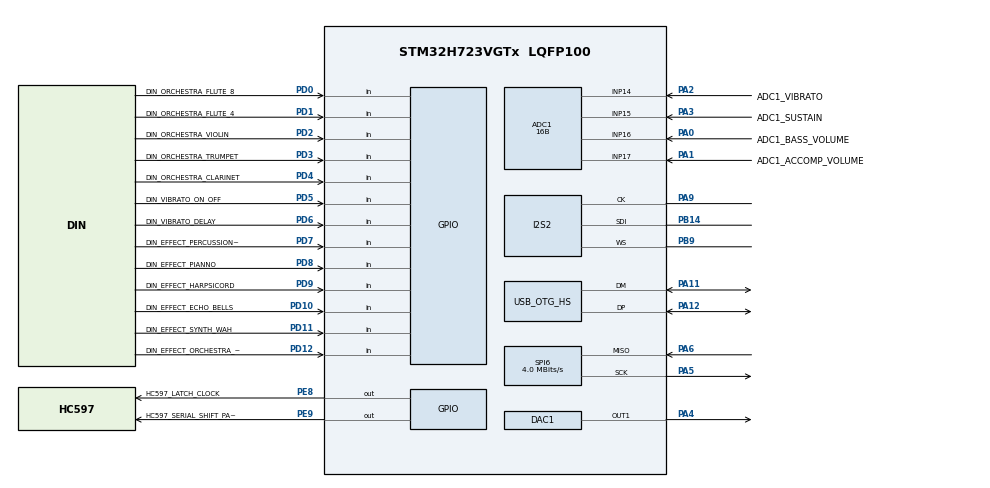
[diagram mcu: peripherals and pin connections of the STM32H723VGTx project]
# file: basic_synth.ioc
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ADC1.Channel-0\#ChannelRegularConversion=ADC_CHANNEL_14
ADC1.Channel-5\#ChannelRegularConversion=ADC_CHANNEL_15
ADC1.Channel-6\#ChannelRegularConversion=ADC_CHANNEL_16
ADC1.Channel-7\#ChannelRegularConversion=ADC_CHANNEL_17
ADC1.ClockPrescaler=ADC_CLOCK_SYNC_PCLK_DIV4
ADC1.ContinuousConvMode=ENABLE
ADC1.ConversionDataManagement=ADC_CONVERSIONDATA_DMA_CIRCULAR
ADC1.EOCSelection=ADC_EOC_SINGLE_CONV
ADC1.ExternalTrigConv=ADC_EXTERNALTRIG_T6_TRGO
ADC1.NbrOfConversion=4
ADC1.NbrOfConversionFlag=1
ADC1.OffsetNumber-0\#ChannelRegularConversion=ADC_OFFSET_NONE
ADC1.OffsetNumber-5\#ChannelRegularConversion=ADC_OFFSET_NONE
ADC1.OffsetNumber-6\#ChannelRegularConversion=ADC_OFFSET_NONE
ADC1.OffsetNumber-7\#ChannelRegularConversion=ADC_OFFSET_NONE
ADC1.OffsetSignedSaturation-0\#ChannelRegularConversion=DISABLE
ADC1.OffsetSignedSaturation-5\#ChannelRegularConversion=DISABLE
ADC1.OffsetSignedSaturation-6\#ChannelRegularConversion=DISABLE
ADC1.OffsetSignedSaturation-7\#ChannelRegularConversion=DISABLE
ADC1.Rank-0\#ChannelRegularConversion=1
ADC1.Rank-5\#ChannelRegularConversion=2
ADC1.Rank-6\#ChannelRegularConversion=3
ADC1.Rank-7\#ChannelRegularConversion=4
ADC1.Resolution=ADC_RESOLUTION_16B
ADC1.SamplingTime-0\#ChannelRegularConversion=ADC_SAMPLETIME_1CYCLE_5
ADC1.SamplingTime-5\#ChannelRegularConversion=ADC_SAMPLETIME_1CYCLE_5
ADC1.SamplingTime-6\#ChannelRegularConversion=ADC_SAMPLETIME_1CYCLE_5
ADC1.SamplingTime-7\#ChannelRegularConversion=ADC_SAMPLETIME_1CYCLE_5
ADC1.master=1
CORTEX_M7.default_mode_Activation=1
DAC1.DAC1_OutputBuffer-DAC_OUT1=DAC_OUTPUTBUFFER_ENABLE
DAC1.DAC_Channel-DAC_OUT1=DAC_CHANNEL_1
DAC1.DAC_Trigger-DAC_OUT1=DAC_TRIGGER_T7_TRGO
Dma.ADC1.0.Direction=DMA_PERIPH_TO_MEMORY
Dma.ADC1.0.EventEnable=DISABLE
Dma.ADC1.0.FIFOMode=DMA_FIFOMODE_DISABLE
Dma.ADC1.0.Instance=DMA2_Stream0
Dma.ADC1.0.MemDataAlignment=DMA_MDATAALIGN_WORD
Dma.ADC1.0.MemInc=DMA_MINC_ENABLE
Dma.ADC1.0.Mode=DMA_CIRCULAR
Dma.ADC1.0.PeriphDataAlignment=DMA_PDATAALIGN_WORD
Dma.ADC1.0.PeriphInc=DMA_PINC_DISABLE
Dma.ADC1.0.Polarity=HAL_DMAMUX_REQ_GEN_RISING
Dma.ADC1.0.Priority=DMA_PRIORITY_LOW
Dma.ADC1.0.RequestNumber=1
Dma.ADC1.0.SignalID=NONE
Dma.ADC1.0.SyncEnable=DISABLE
Dma.ADC1.0.SyncPolarity=HAL_DMAMUX_SYNC_NO_EVENT
Dma.ADC1.0.SyncRequestNumber=1
Dma.ADC1.0.SyncSignalID=NONE
Dma.DAC1_CH1.1.Direction=DMA_MEMORY_TO_PERIPH
Dma.DAC1_CH1.1.EventEnable=DISABLE
Dma.DAC1_CH1.1.FIFOMode=DMA_FIFOMODE_DISABLE
Dma.DAC1_CH1.1.Instance=DMA1_Stream0
Dma.DAC1_CH1.1.MemDataAlignment=DMA_MDATAALIGN_WORD
Dma.DAC1_CH1.1.MemInc=DMA_MINC_ENABLE
Dma.DAC1_CH1.1.Mode=DMA_CIRCULAR
Dma.DAC1_CH1.1.PeriphDataAlignment=DMA_PDATAALIGN_WORD
Dma.DAC1_CH1.1.PeriphInc=DMA_PINC_DISABLE
Dma.DAC1_CH1.1.Polarity=HAL_DMAMUX_REQ_GEN_RISING
Dma.DAC1_CH1.1.Priority=DMA_PRIORITY_LOW
Dma.DAC1_CH1.1.RequestNumber=1
Dma.DAC1_CH1.1.SignalID=NONE
Dma.DAC1_CH1.1.SyncEnable=DISABLE
Dma.DAC1_CH1.1.SyncPolarity=HAL_DMAMUX_SYNC_NO_EVENT
Dma.DAC1_CH1.1.SyncRequestNumber=1
Dma.DAC1_CH1.1.SyncSignalID=NONE
Dma.Request0=ADC1
Dma.Request1=DAC1_CH1
Dma.Request2=SPI2_RX
Dma.SPI2_RX.2.Direction=DMA_PERIPH_TO_MEMORY
Dma.SPI2_RX.2.EventEnable=DISABLE
Dma.SPI2_RX.2.FIFOMode=DMA_FIFOMODE_DISABLE
Dma.SPI2_RX.2.Instance=DMA1_Stream1
Dma.SPI2_RX.2.MemDataAlignment=DMA_MDATAALIGN_HALFWORD
Dma.SPI2_RX.2.MemInc=DMA_MINC_ENABLE
Dma.SPI2_RX.2.Mode=DMA_CIRCULAR
Dma.SPI2_RX.2.PeriphDataAlignment=DMA_PDATAALIGN_HALFWORD
Dma.SPI2_RX.2.PeriphInc=DMA_PINC_DISABLE
Dma.SPI2_RX.2.Polarity=HAL_DMAMUX_REQ_GEN_RISING
Dma.SPI2_RX.2.Priority=DMA_PRIORITY_HIGH
Dma.SPI2_RX.2.RequestNumber=1
Dma.SPI2_RX.2.SignalID=NONE
Dma.SPI2_RX.2.SyncEnable=DISABLE
Dma.SPI2_RX.2.SyncPolarity=HAL_DMAMUX_SYNC_NO_EVENT
Dma.SPI2_RX.2.SyncRequestNumber=1
Dma.SPI2_RX.2.SyncSignalID=NONE
I2S2.AudioFreq=AudioFreqCustomValue
I2S2.AudioFreqCustom=44100
I2S2.ErrorAudioFreq=0.15 %
I2S2.Instance=SPI$Index
I2S2.RealAudioFreq=44.07 KHz
Mcu.Family=STM32H7
Mcu.Name=STM32H723VGTx
Mcu.Package=LQFP100
NVIC.DMA1_Stream0_IRQn=true\:0\:0\:false\:false\:true\:false\:true\:true
NVIC.DMA1_Stream1_IRQn=true\:0\:0\:false\:false\:true\:false\:true\:true
NVIC.DMA2_Stream0_IRQn=true\:0\:0\:false\:false\:true\:false\:true\:true
NVIC.OTG_HS_IRQn=true\:0\:0\:false\:false\:true\:false\:true\:true
NVIC.PriorityGroup=NVIC_PRIORITYGROUP_4
PA0.GPIO_Label=ADC1_BASS_VOLUME
PA0.Mode=IN16-Single-Ended
PA0.Signal=ADC1_INP16
PA1.GPIO_Label=ADC1_ACCOMP_VOLUME
PA1.Mode=IN17-Single-Ended
PA1.Signal=ADC1_INP17
PA11.Mode=Device_Only_FS
PA11.Signal=USB_OTG_HS_DM
PA12.Mode=Device_Only_FS
PA12.Signal=USB_OTG_HS_DP
PA2.GPIO_Label=ADC1_VIBRATO
PA2.Signal=ADCx_INP14
PA3.GPIO_Label=ADC1_SUSTAIN
PA3.Signal=ADCx_INP15
PA4.Signal=COMP_DAC11_group
PA5.Mode=RX_Only_Simplex_Unidirect_Master
PA5.Signal=SPI6_SCK
PA6.Mode=RX_Only_Simplex_Unidirect_Master
PA6.Signal=SPI6_MISO
PA9.Mode=Half_Duplex_Master_Rx
PA9.Signal=I2S2_CK
PB14.Mode=Half_Duplex_Master_Rx
PB14.Signal=I2S2_SDI
PB9.Mode=Half_Duplex_Master_Rx
PB9.Signal=I2S2_WS
PD0.GPIO_Label=DIN_ORCHESTRA_FLUTE_8
PD0.GPIO_PuPd=GPIO_PULLUP
PD0.Signal=GPIO_Input
PD1.GPIO_Label=DIN_ORCHESTRA_FLUTE_4
PD1.GPIO_PuPd=GPIO_PULLUP
PD1.Signal=GPIO_Input
PD10.GPIO_Label=DIN_EFFECT_ECHO_BELLS
PD10.GPIO_PuPd=GPIO_PULLUP
PD10.Signal=GPIO_Input
PD11.GPIO_Label=DIN_EFFECT_SYNTH_WAH
PD11.GPIO_PuPd=GPIO_PULLUP
PD11.Signal=GPIO_Input
PD12.GPIO_Label=DIN_EFFECT_ORCHESTRA_CANCEL
PD12.GPIO_PuPd=GPIO_PULLUP
PD12.Signal=GPIO_Input
PD2.GPIO_Label=DIN_ORCHESTRA_VIOLIN
PD2.GPIO_PuPd=GPIO_PULLUP
PD2.Signal=GPIO_Input
PD3.GPIO_Label=DIN_ORCHESTRA_TRUMPET
PD3.GPIO_PuPd=GPIO_PULLUP
PD3.Signal=GPIO_Input
PD4.GPIO_Label=DIN_ORCHESTRA_CLARINET
PD4.GPIO_PuPd=GPIO_PULLUP
PD4.Signal=GPIO_Input
PD5.GPIO_Label=DIN_VIBRATO_ON_OFF
PD5.GPIO_PuPd=GPIO_PULLUP
PD5.Signal=GPIO_Input
PD6.GPIO_Label=DIN_VIBRATO_DELAY
PD6.GPIO_PuPd=GPIO_PULLUP
PD6.Signal=GPIO_Input
PD7.GPIO_Label=DIN_EFFECT_PERCUSSION_4
PD7.GPIO_PuPd=GPIO_PULLUP
PD7.Signal=GPIO_Input
PD8.GPIO_Label=DIN_EFFECT_PIANNO
PD8.GPIO_PuPd=GPIO_PULLUP
PD8.Signal=GPIO_Input
PD9.GPIO_Label=DIN_EFFECT_HARPSICORD
PD9.GPIO_PuPd=GPIO_PULLUP
PD9.Signal=GPIO_Input
PE8.GPIO_Label=HC597_LATCH_CLOCK
PE8.Signal=GPIO_Output
PE9.GPIO_Label=HC597_SERIAL_SHIFT_PARALLEL_LOAD
PE9.Signal=GPIO_Output
PH0-OSC_IN.Mode=HSE-External-Oscillator
PH0-OSC_IN.Signal=RCC_OSC_IN
PH1-OSC_OUT.Mode=HSE-External-Oscillator
PH1-OSC_OUT.Signal=RCC_OSC_OUT
ProjectManager.HeapSize=0x200
ProjectManager.StackSize=0x400
ProjectManager.TargetToolchain=STM32CubeIDE
RCC.ADCFreq_Value=55000000
RCC.APB1Freq_Value=137500000
RCC.APB2Freq_Value=137500000
RCC.APB3Freq_Value=137500000
RCC.APB4Freq_Value=137500000
RCC.CortexFreq_Value=550000000
RCC.D1PPRE=RCC_APB3_DIV2
RCC.D2PPRE1=RCC_APB1_DIV2
RCC.D2PPRE2=RCC_APB2_DIV2
RCC.D3PPRE=RCC_APB4_DIV2
RCC.DIVM1=2
RCC.DIVM2=2
RCC.DIVM3=20
RCC.DIVN1=44
RCC.DIVN2=44
RCC.DIVN3=168
RCC.DIVP1=1
RCC.DIVP2=10
RCC.DIVP3=1
RCC.DIVQ1=10
RCC.DIVQ2=10
RCC.HCLKFreq_Value=275000000
RCC.HPRE=RCC_HCLK_DIV2
RCC.PLL2FRACN=0
RCC.PLL3FRACN=0
RCC.PLLFRACN=0
RCC.PLLSourceVirtual=RCC_PLLSOURCE_HSE
RCC.SPI123CLockSelection=RCC_SPI123CLKSOURCE_PLL2
RCC.SPI6CLockSelection=RCC_SPI6CLKSOURCE_HSI
RCC.SYSCLKFreq_VALUE=550000000
RCC.SYSCLKSource=RCC_SYSCLKSOURCE_PLLCLK
RCC.USBCLockSelection=RCC_USBCLKSOURCE_HSI48
RCC.USBFreq_Value=48000000
SH.ADCx_INP14.0=ADC1_INP14,IN14-Single-Ended
SH.ADCx_INP15.0=ADC1_INP15,IN15-Single-Ended
SH.COMP_DAC11_group.0=DAC1_OUT1,DAC_OUT1
SPI6.BaudRatePrescaler=SPI_BAUDRATEPRESCALER_16
SPI6.CalculateBaudRate=4.0 MBits/s
SPI6.DataSize=SPI_DATASIZE_8BIT
SPI6.Direction=SPI_DIRECTION_2LINES_RXONLY
SPI6.FirstBit=SPI_FIRSTBIT_LSB
SPI6.Mode=SPI_MODE_MASTER
SPI6.VirtualType=VM_MASTER
TIM6.Prescaler=128
TIM6.TIM_MasterOutputTrigger=TIM_TRGO_UPDATE
TIM7.Period=6239
TIM7.Prescaler=0
TIM7.TIM_MasterOutputTrigger=TIM_TRGO_UPDATE
USB_DEVICE.CLASS_NAME_HS=HID
USB_DEVICE.MANUFACTURER_STRING=EKO
USB_DEVICE.PRODUCT_STRING_HID_HS=EKO TIGER P61
USB_DEVICE.VirtualMode=Hid
USB_DEVICE.VirtualModeHS=Hid_HS
USB_OTG_HS.VirtualMode-Device_Only_FS=Device_Only_FS
VP_TIM6_VS_ClockSourceINT.Mode=Enable_Timer
VP_TIM7_VS_ClockSourceINT.Mode=Enable_Timer
VP_USB_DEVICE_VS_USB_DEVICE_HID_HS.Mode=HID_HS
board=custom

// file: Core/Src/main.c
/* USER CODE BEGIN Header */
/**
  ******************************************************************************
  * @file           : main.c
  * @brief          : Main program body
  ******************************************************************************
  * @attention
  *
  * Copyright (c) 2024 STMicroelectronics.
  * All rights reserved.
  *
  * This software is licensed under terms that can be found in the LICENSE file
  * in the root directory of this software component.
  * If no LICENSE file comes with this software, it is provided AS-IS.
  *
  ******************************************************************************
  */
/* USER CODE END Header */
#include "main.h"
#include "adc.h"
#include "dac.h"
#include "dma.h"
#include "i2s.h"
#include "spi.h"
#include "tim.h"
#include "usb_device.h"
#include "gpio.h"

/* USER CODE BEGIN Includes */
#include "eko_tiger_p61.h"

/* USER CODE END Includes */

void SystemClock_Config(void);
static void MPU_Config(void);

int main(void)
{

  /* MPU Configuration--------------------------------------------------------*/
  MPU_Config();

  /* MCU Configuration--------------------------------------------------------*/

  /* Reset of all peripherals, Initializes the Flash interface and the Systick. */
  HAL_Init();

  /* Configure the system clock */
  SystemClock_Config();

  /* Initialize all configured peripherals */
  MX_GPIO_Init();
  MX_DMA_Init();
  MX_USB_DEVICE_Init();
  MX_SPI6_Init();
  MX_ADC1_Init();
  MX_TIM6_Init();
  MX_DAC1_Init();
  MX_TIM7_Init();
  MX_I2S2_Init();
  /* USER CODE BEGIN 2 */

  eko_tiger_p61_setup();

  /* USER CODE END 2 */

  /* Infinite loop */
  /* USER CODE BEGIN WHILE */

  eko_tiger_p61_loop();

    /* USER CODE END WHILE */

}

void SystemClock_Config(void)
{
  RCC_OscInitTypeDef RCC_OscInitStruct = {0};
  RCC_ClkInitTypeDef RCC_ClkInitStruct = {0};

  /** Supply configuration update enable
  */
  HAL_PWREx_ConfigSupply(PWR_LDO_SUPPLY);

  /** Configure the main internal regulator output voltage
  */
  __HAL_PWR_VOLTAGESCALING_CONFIG(PWR_REGULATOR_VOLTAGE_SCALE0);

  while(!__HAL_PWR_GET_FLAG(PWR_FLAG_VOSRDY)) {}

  /** Initializes the RCC Oscillators according to the specified parameters
  * in the RCC_OscInitTypeDef structure.
  */
  RCC_OscInitStruct.OscillatorType = RCC_OSCILLATORTYPE_HSI48|RCC_OSCILLATORTYPE_HSI
                              |RCC_OSCILLATORTYPE_HSE;
  RCC_OscInitStruct.HSEState = RCC_HSE_ON;
  RCC_OscInitStruct.HSIState = RCC_HSI_DIV1;
  RCC_OscInitStruct.HSICalibrationValue = 64;
  RCC_OscInitStruct.HSI48State = RCC_HSI48_ON;
  RCC_OscInitStruct.PLL.PLLState = RCC_PLL_ON;
  RCC_OscInitStruct.PLL.PLLSource = RCC_PLLSOURCE_HSE;
  RCC_OscInitStruct.PLL.PLLM = 2;
  RCC_OscInitStruct.PLL.PLLN = 44;
  RCC_OscInitStruct.PLL.PLLP = 1;
  RCC_OscInitStruct.PLL.PLLQ = 10;
  RCC_OscInitStruct.PLL.PLLR = 2;
  RCC_OscInitStruct.PLL.PLLRGE = RCC_PLL1VCIRANGE_3;
  RCC_OscInitStruct.PLL.PLLVCOSEL = RCC_PLL1VCOWIDE;
  RCC_OscInitStruct.PLL.PLLFRACN = 0;
  if (HAL_RCC_OscConfig(&RCC_OscInitStruct) != HAL_OK)
  {
    Error_Handler();
  }

  /** Initializes the CPU, AHB and APB buses clocks
  */
  RCC_ClkInitStruct.ClockType = RCC_CLOCKTYPE_HCLK|RCC_CLOCKTYPE_SYSCLK
                              |RCC_CLOCKTYPE_PCLK1|RCC_CLOCKTYPE_PCLK2
                              |RCC_CLOCKTYPE_D3PCLK1|RCC_CLOCKTYPE_D1PCLK1;
  RCC_ClkInitStruct.SYSCLKSource = RCC_SYSCLKSOURCE_PLLCLK;
  RCC_ClkInitStruct.SYSCLKDivider = RCC_SYSCLK_DIV1;
  RCC_ClkInitStruct.AHBCLKDivider = RCC_HCLK_DIV2;
  RCC_ClkInitStruct.APB3CLKDivider = RCC_APB3_DIV2;
  RCC_ClkInitStruct.APB1CLKDivider = RCC_APB1_DIV2;
  RCC_ClkInitStruct.APB2CLKDivider = RCC_APB2_DIV2;
  RCC_ClkInitStruct.APB4CLKDivider = RCC_APB4_DIV2;

  if (HAL_RCC_ClockConfig(&RCC_ClkInitStruct, FLASH_LATENCY_3) != HAL_OK)
  {
    Error_Handler();
  }
}

 /* MPU Configuration */

void MPU_Config(void)
{
  MPU_Region_InitTypeDef MPU_InitStruct = {0};

  /* Disables the MPU */
  HAL_MPU_Disable();

  /** Initializes and configures the Region and the memory to be protected
  */
  MPU_InitStruct.Enable = MPU_REGION_ENABLE;
  MPU_InitStruct.Number = MPU_REGION_NUMBER0;
  MPU_InitStruct.BaseAddress = 0x0;
  MPU_InitStruct.Size = MPU_REGION_SIZE_4GB;
  MPU_InitStruct.SubRegionDisable = 0x87;
  MPU_InitStruct.TypeExtField = MPU_TEX_LEVEL0;
  MPU_InitStruct.AccessPermission = MPU_REGION_NO_ACCESS;
  MPU_InitStruct.DisableExec = MPU_INSTRUCTION_ACCESS_DISABLE;
  MPU_InitStruct.IsShareable = MPU_ACCESS_SHAREABLE;
  MPU_InitStruct.IsCacheable = MPU_ACCESS_NOT_CACHEABLE;
  MPU_InitStruct.IsBufferable = MPU_ACCESS_NOT_BUFFERABLE;

  HAL_MPU_ConfigRegion(&MPU_InitStruct);
  /* Enables the MPU */
  HAL_MPU_Enable(MPU_PRIVILEGED_DEFAULT);

}

void Error_Handler(void)
{
  __disable_irq();
  while (1)
  {
  }
}
